VERSION ""

NS_ :

BS_:

BU_: NOONE SENSOR DRIVER MOTOR IO

BO_ 100 HEARTBEAT: 1 DRIVER
 SG_ DRIVER_HEARTBEAT_cmd : 0|8@1+ (1,0) [0|0] "" SENSOR,MOTOR

BO_ 140 HEARTBEAT: 1 SENSOR
 SG_ DRIVER_HEARTBEAT_cmd : 0|8@1+ (1,0) [0|0] "" DRIVER

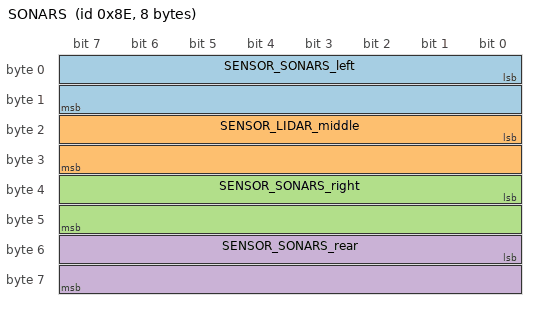
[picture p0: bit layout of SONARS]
BO_ 142 SONARS: 8 SENSOR
 SG_ SENSOR_SONARS_left : 0|16@1+ (1,0) [0|0] "" DRIVER,IO
 SG_ SENSOR_LIDAR_middle : 16|16@1+ (1,0) [0|0] "" DRIVER,IO
 SG_ SENSOR_SONARS_right : 32|16@1+ (1,0) [0|0] "" DRIVER,IO
 SG_ SENSOR_SONARS_rear : 48|16@1+ (1,0) [0|0] "" DRIVER,IO

 BO_ 144 BATTERY: 2 SENSOR
 SG_ SENSORS_BATTERY : 0|16@1+ (1,0) [0|0] "" DRIVER, IO

BO_ 300 MOTOR_CMD: 1 DRIVER
 SG_ MOTOR_CMD_steer : 0|4@1- (1,-5) [-5|5] "" MOTOR
 SG_ MOTOR_CMD_drive : 4|4@1+ (1,0) [0|9] "" MOTOR

CM_ BU_ NOONE "No node, used to indicate if it's a debug message going to no one";
CM_ BU_ DRIVER "The driver controller driving the car";
CM_ BU_ SENSOR "The sensor controller of the car";
CM_ BU_ MOTOR "The motor controller of the car";
CM_ BO_ 100 "Sync message used to synchronize the controllers";

BA_DEF_  "BusType" STRING ;
BA_DEF_ SG_ "FieldType" STRING ;
BA_DEF_ BO_ "GenMsgCycleTime" INT 0 0;

BA_DEF_DEF_ "BusType" "CAN";
BA_DEF_DEF_ "FieldType" "";

BA_ "GenMsgCycleTime" BO_ 100 1000;
BA_ "GenMsgCycleTime" BO_ 200 100;
BA_ "GenMsgCycleTime" BO_ 300 100;
BA_ "FieldType" SG_ 100 DRIVER_HEARTBEAT_cmd "DRIVER_HEARTBEAT_cmd";

VAL_ 100 DRIVER_HEARTBEAT_cmd 0 "DRIVER_HEARTBEAT_cmd_NOOP" 1 "DRIVER_HEARTBEAT_cmd_SYNC" 2 "DRIVER_HEARTBEAT_cmd_REBOOT";
